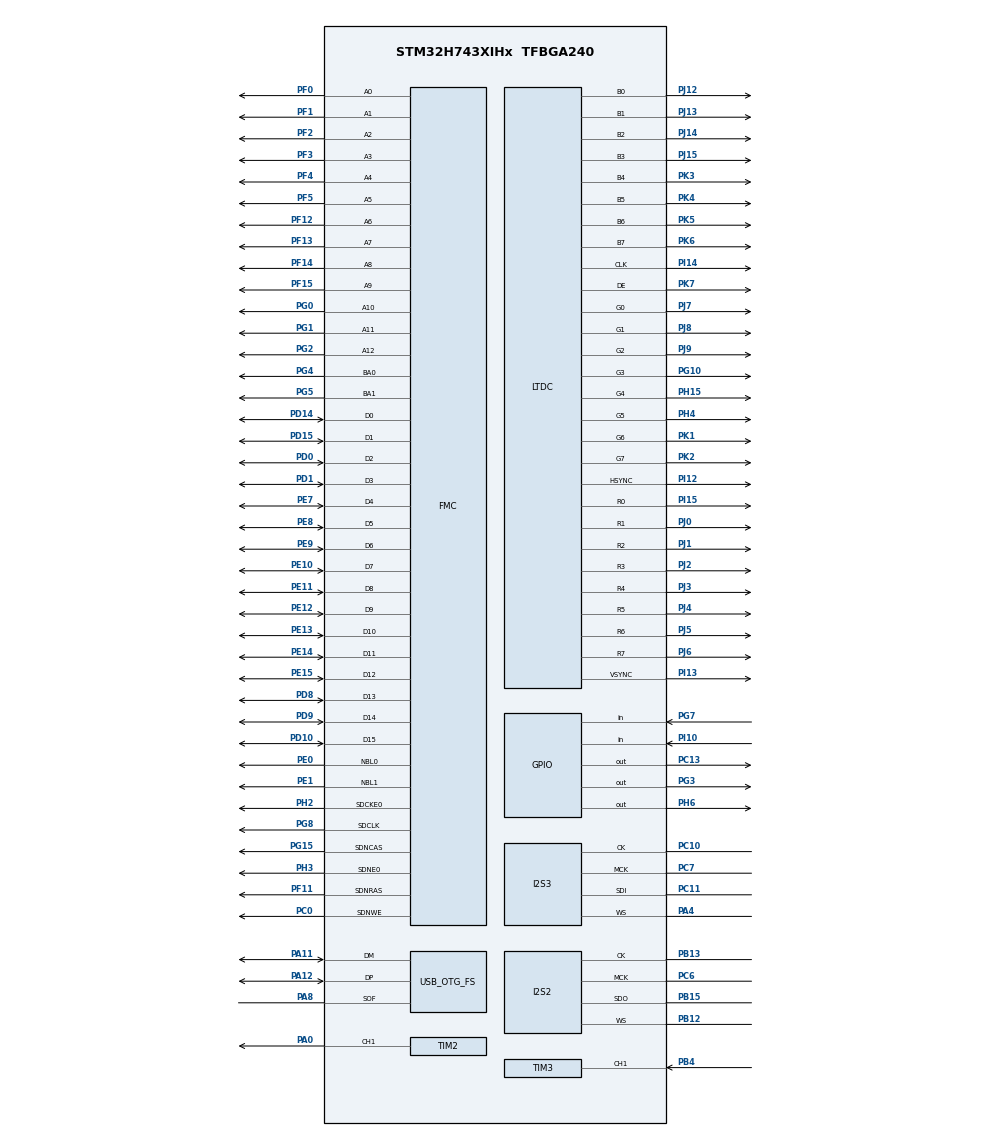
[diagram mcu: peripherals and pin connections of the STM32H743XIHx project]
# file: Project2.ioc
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CORTEX_M7.AccessPermission_S-Cortex_Memory_Protection_Unit_Region1_Settings_S=MPU_REGION_FULL_ACCESS
CORTEX_M7.AccessPermission_Spec=MPU_REGION_FULL_ACCESS
CORTEX_M7.BaseAddress_S-Cortex_Memory_Protection_Unit_Region1_Settings_S=0xC0000000
CORTEX_M7.BaseAddress_Spec=0x24000000
CORTEX_M7.CPU_DCache=Enabled
CORTEX_M7.CPU_ICache=Enabled
CORTEX_M7.DisableExec_Spec=MPU_INSTRUCTION_ACCESS_ENABLE
CORTEX_M7.Enable_S-Cortex_Memory_Protection_Unit_Region1_Settings_S=MPU_REGION_ENABLE
CORTEX_M7.Enable_Spec=MPU_REGION_ENABLE
CORTEX_M7.IsBufferable_S-Cortex_Memory_Protection_Unit_Region1_Settings_S=MPU_ACCESS_BUFFERABLE
CORTEX_M7.IsBufferable_Spec=MPU_ACCESS_BUFFERABLE
CORTEX_M7.IsCacheable_S-Cortex_Memory_Protection_Unit_Region1_Settings_S=MPU_ACCESS_CACHEABLE
CORTEX_M7.IsCacheable_Spec=MPU_ACCESS_CACHEABLE
CORTEX_M7.IsShareable_Spec=MPU_ACCESS_NOT_SHAREABLE
CORTEX_M7.MPU_Control=MPU_HFNMI_PRIVDEF
CORTEX_M7.Number_S-Cortex_Memory_Protection_Unit_Region2_Settings_S=MPU_REGION_NUMBER2
CORTEX_M7.Size_S-Cortex_Memory_Protection_Unit_Region1_Settings_S=MPU_REGION_SIZE_8MB
CORTEX_M7.Size_Spec=MPU_REGION_SIZE_512KB
CORTEX_M7.SubRegionDisable_Spec=0x0
CORTEX_M7.TypeExtField_S-Cortex_Memory_Protection_Unit_Region1_Settings_S=MPU_TEX_LEVEL0
CORTEX_M7.TypeExtField_Spec=MPU_TEX_LEVEL1
CORTEX_M7.default_mode_Activation=1
DMA2D.ColorMode=DMA2D_OUTPUT_RGB565
Dma.Request0=SPI2_TX
Dma.Request1=SPI3_RX
Dma.SPI2_TX.0.Direction=DMA_MEMORY_TO_PERIPH
Dma.SPI2_TX.0.EventEnable=DISABLE
Dma.SPI2_TX.0.FIFOMode=DMA_FIFOMODE_DISABLE
Dma.SPI2_TX.0.Instance=DMA1_Stream0
Dma.SPI2_TX.0.MemDataAlignment=DMA_MDATAALIGN_WORD
Dma.SPI2_TX.0.MemInc=DMA_MINC_ENABLE
Dma.SPI2_TX.0.Mode=DMA_CIRCULAR
Dma.SPI2_TX.0.PeriphDataAlignment=DMA_PDATAALIGN_WORD
Dma.SPI2_TX.0.PeriphInc=DMA_PINC_DISABLE
Dma.SPI2_TX.0.Polarity=HAL_DMAMUX_REQ_GEN_RISING
Dma.SPI2_TX.0.Priority=DMA_PRIORITY_LOW
Dma.SPI2_TX.0.RequestNumber=1
Dma.SPI2_TX.0.SignalID=NONE
Dma.SPI2_TX.0.SyncEnable=DISABLE
Dma.SPI2_TX.0.SyncPolarity=HAL_DMAMUX_SYNC_NO_EVENT
Dma.SPI2_TX.0.SyncRequestNumber=1
Dma.SPI2_TX.0.SyncSignalID=NONE
Dma.SPI3_RX.1.Direction=DMA_PERIPH_TO_MEMORY
Dma.SPI3_RX.1.EventEnable=DISABLE
Dma.SPI3_RX.1.FIFOMode=DMA_FIFOMODE_DISABLE
Dma.SPI3_RX.1.Instance=DMA1_Stream1
Dma.SPI3_RX.1.MemDataAlignment=DMA_MDATAALIGN_WORD
Dma.SPI3_RX.1.MemInc=DMA_MINC_ENABLE
Dma.SPI3_RX.1.Mode=DMA_CIRCULAR
Dma.SPI3_RX.1.PeriphDataAlignment=DMA_PDATAALIGN_WORD
Dma.SPI3_RX.1.PeriphInc=DMA_PINC_DISABLE
Dma.SPI3_RX.1.Polarity=HAL_DMAMUX_REQ_GEN_RISING
Dma.SPI3_RX.1.Priority=DMA_PRIORITY_LOW
Dma.SPI3_RX.1.RequestNumber=1
Dma.SPI3_RX.1.SignalID=NONE
Dma.SPI3_RX.1.SyncEnable=DISABLE
Dma.SPI3_RX.1.SyncPolarity=HAL_DMAMUX_SYNC_NO_EVENT
Dma.SPI3_RX.1.SyncRequestNumber=1
Dma.SPI3_RX.1.SyncSignalID=NONE
FMC.CASLatency1=FMC_SDRAM_CAS_LATENCY_3
FMC.ColumnBitsNumber1=FMC_SDRAM_COLUMN_BITS_NUM_9
FMC.ExitSelfRefreshDelay1=5
FMC.LoadToActiveDelay1=2
FMC.RCDDelay1=2
FMC.RPDelay1=2
FMC.RPDelay2=2
FMC.ReadBurst1=FMC_SDRAM_RBURST_ENABLE
FMC.ReadBurst2=FMC_SDRAM_RBURST_ENABLE
FMC.ReadPipeDelay1=FMC_SDRAM_RPIPE_DELAY_0
FMC.RowCycleDelay1=7
FMC.RowCycleDelay2=7
FMC.SDClockPeriod1=FMC_SDRAM_CLOCK_PERIOD_2
FMC.SDClockPeriod2=FMC_SDRAM_CLOCK_PERIOD_2
FMC.SelfRefreshTime1=4
FMC.WriteRecoveryTime1=3
FREERTOS.Tasks01=DisplayTask,8,2048,DisplayTaskEntry,Default,NULL,Static,DisplayTaskBuffer,DisplayTaskControlBlock;DatacollecTask,40,1024,DatacollecTaskEntry,Default,NULL,Static,DatacollecTaskBuffer,DatacollecTaskControlBlock
FREERTOS.configENABLE_FPU=1
FREERTOS.configUSE_IDLE_HOOK=1
FREERTOS.configUSE_TICK_HOOK=1
I2S2.AudioFreq=I2S_AUDIOFREQ_48K
I2S2.DataFormat=I2S_DATAFORMAT_24B
I2S2.ErrorAudioFreq=0.0 %
I2S2.Instance=SPI$Index
I2S2.RealAudioFreq=48.0 KHz
I2S3.AudioFreq=I2S_AUDIOFREQ_48K
I2S3.DataFormat=I2S_DATAFORMAT_24B
I2S3.ErrorAudioFreq=0.0 %
I2S3.FirstBit=I2S_FIRSTBIT_MSB
I2S3.Instance=SPI$Index
I2S3.RealAudioFreq=48.0 KHz
LTDC.ActiveW=800
LTDC.Alpha_L0=255
LTDC.FBStartAdress_L0=0xC0000000
LTDC.FBStartAdress_L1=0xC00BB800
LTDC.HBP=80
LTDC.HFP=200
LTDC.HSync=1
LTDC.ImageHeight_L0=480
LTDC.ImageHeight_L1=480
LTDC.ImageWidth_L0=800
LTDC.Layers=0
LTDC.PixelFormat_L0=LTDC_PIXEL_FORMAT_RGB565
LTDC.VBP=20
LTDC.VFP=22
LTDC.VSync=1
LTDC.WindowX1_L0=800
LTDC.WindowY1_L0=480
Mcu.Family=STM32H7
Mcu.Name=STM32H743XIHx
Mcu.Package=TFBGA240
NVIC.DMA1_Stream0_IRQn=true\:5\:0\:false\:false\:true\:false\:false\:true\:true
NVIC.DMA1_Stream1_IRQn=true\:5\:0\:false\:false\:true\:false\:false\:true\:true
NVIC.DMA2D_IRQn=true\:5\:0\:false\:false\:true\:true\:true\:true\:true
NVIC.OTG_FS_IRQn=true\:5\:0\:false\:false\:true\:true\:false\:true\:true
NVIC.PriorityGroup=NVIC_PRIORITYGROUP_4
NVIC.SPI2_IRQn=true\:5\:0\:false\:false\:true\:true\:true\:true\:true
NVIC.SPI3_IRQn=true\:5\:0\:false\:false\:true\:true\:true\:true\:true
NVIC.TIM3_IRQn=true\:5\:0\:false\:false\:true\:true\:true\:true\:true
NVIC.TIM6_DAC_IRQn=true\:15\:0\:false\:false\:true\:false\:false\:true\:true
NVIC.TimeBase=TIM6_DAC_IRQn
NVIC.TimeBaseIP=TIM6
PA0.Signal=S_TIM2_CH1_ETR
PA11.Mode=Device_Only
PA11.Signal=USB_OTG_FS_DM
PA12.Mode=Device_Only
PA12.Signal=USB_OTG_FS_DP
PA13\ (JTMS/SWDIO).Mode=Serial_Wire
PA13\ (JTMS/SWDIO).Signal=DEBUG_JTMS-SWDIO
PA14\ (JTCK/SWCLK).Mode=Serial_Wire
PA14\ (JTCK/SWCLK).Signal=DEBUG_JTCK-SWCLK
PA15\ (JTDI).Signal=DEBUG_JTDI
PA4.GPIO_Speed=GPIO_SPEED_FREQ_VERY_HIGH
PA4.Mode=Half_Duplex_Master_Rx
PA4.Signal=I2S3_WS
PA8.Mode=Activate_SOF_FS
PA8.Signal=USB_OTG_FS_SOF
PB12.GPIO_Speed=GPIO_SPEED_FREQ_VERY_HIGH
PB12.Mode=Half_Duplex_Master_Tx
PB12.Signal=I2S2_WS
PB13.GPIO_Speed=GPIO_SPEED_FREQ_VERY_HIGH
PB13.Mode=Half_Duplex_Master_Tx
PB13.Signal=I2S2_CK
PB15.GPIO_Speed=GPIO_SPEED_FREQ_VERY_HIGH
PB15.Mode=Half_Duplex_Master_Tx
PB15.Signal=I2S2_SDO
PB4\ (NJTRST).Signal=S_TIM3_CH1
PC0.Signal=FMC_SDNWE
PC10.GPIO_Speed=GPIO_SPEED_FREQ_VERY_HIGH
PC10.Mode=Half_Duplex_Master_Rx
PC10.Signal=I2S3_CK
PC11.GPIO_Speed=GPIO_SPEED_FREQ_VERY_HIGH
PC11.Mode=Half_Duplex_Master_Rx
PC11.Signal=I2S3_SDI
PC13.Signal=GPIO_Output
PC14-OSC32_IN\ (OSC32_IN).Mode=LSE-External-Oscillator
PC14-OSC32_IN\ (OSC32_IN).Signal=RCC_OSC32_IN
PC15-OSC32_OUT\ (OSC32_OUT).Mode=LSE-External-Oscillator
PC15-OSC32_OUT\ (OSC32_OUT).Signal=RCC_OSC32_OUT
PC6.GPIO_Speed=GPIO_SPEED_FREQ_VERY_HIGH
PC6.Mode=Master_Clock_Activated
PC6.Signal=I2S2_MCK
PC7.GPIO_Speed=GPIO_SPEED_FREQ_VERY_HIGH
PC7.Mode=Master_Clock_Activated
PC7.Signal=I2S3_MCK
PD0.Signal=FMC_D2_DA2
PD1.Signal=FMC_D3_DA3
PD10.Signal=FMC_D15_DA15
PD14.Signal=FMC_D0_DA0
PD15.Signal=FMC_D1_DA1
PD8.Signal=FMC_D13_DA13
PD9.Signal=FMC_D14_DA14
PE0.Signal=FMC_NBL0
PE1.Signal=FMC_NBL1
PE10.Signal=FMC_D7_DA7
PE11.Signal=FMC_D8_DA8
PE12.Signal=FMC_D9_DA9
PE13.Signal=FMC_D10_DA10
PE14.Signal=FMC_D11_DA11
PE15.Signal=FMC_D12_DA12
PE7.Signal=FMC_D4_DA4
PE8.Signal=FMC_D5_DA5
PE9.Signal=FMC_D6_DA6
PF0.Signal=FMC_A0
PF1.Signal=FMC_A1
PF11.Signal=FMC_SDNRAS
PF12.Signal=FMC_A6
PF13.Signal=FMC_A7
PF14.Signal=FMC_A8
PF15.Signal=FMC_A9
PF2.Signal=FMC_A2
PF3.Signal=FMC_A3
PF4.Signal=FMC_A4
PF5.PinAttribute=Free
PF5.Signal=FMC_A5
PG0.Signal=FMC_A10
PG1.Signal=FMC_A11
PG10.GPIO_Speed=GPIO_SPEED_FREQ_VERY_HIGH
PG10.Mode=RGB888
PG10.Signal=LTDC_G3
PG15.Signal=FMC_SDNCAS
PG2.Signal=FMC_A12
PG3.Signal=GPIO_Output
PG4.Signal=FMC_A14_BA0
PG5.Signal=FMC_A15_BA1
PG6.GPIO_Speed=GPIO_SPEED_FREQ_VERY_HIGH
PG6.Signal=QUADSPI_BK1_NCS
PG7.Signal=GPIO_Input
PG8.Signal=FMC_SDCLK
PH0-OSC_IN\ (PH0).Mode=HSE-External-Oscillator
PH0-OSC_IN\ (PH0).PinAttribute=Free
PH0-OSC_IN\ (PH0).Signal=RCC_OSC_IN
PH1-OSC_OUT\ (PH1).Mode=HSE-External-Oscillator
PH1-OSC_OUT\ (PH1).PinAttribute=Free
PH1-OSC_OUT\ (PH1).Signal=RCC_OSC_OUT
PH15.GPIO_Speed=GPIO_SPEED_FREQ_VERY_HIGH
PH15.Mode=RGB888
PH15.Signal=LTDC_G4
PH2.Mode=SdramChipSelect1_1
PH2.Signal=FMC_SDCKE0
PH3.Mode=SdramChipSelect1_1
PH3.Signal=FMC_SDNE0
PH4.GPIO_Speed=GPIO_SPEED_FREQ_VERY_HIGH
PH4.Mode=RGB888
PH4.Signal=LTDC_G5
PH6.Signal=GPIO_Output
PI10.Signal=GPIO_Input
PI12.GPIO_Speed=GPIO_SPEED_FREQ_VERY_HIGH
PI12.Mode=RGB888
PI12.Signal=LTDC_HSYNC
PI13.GPIO_Speed=GPIO_SPEED_FREQ_VERY_HIGH
PI13.Mode=RGB888
PI13.Signal=LTDC_VSYNC
PI14.GPIO_Speed=GPIO_SPEED_FREQ_VERY_HIGH
PI14.Mode=RGB888
PI14.PinAttribute=Free
PI14.Signal=LTDC_CLK
PI15.GPIO_Speed=GPIO_SPEED_FREQ_VERY_HIGH
PI15.Mode=RGB888
PI15.Signal=LTDC_R0
PJ0.GPIO_Speed=GPIO_SPEED_FREQ_VERY_HIGH
PJ0.Mode=RGB888
PJ0.Signal=LTDC_R1
PJ1.GPIO_Speed=GPIO_SPEED_FREQ_VERY_HIGH
PJ1.Mode=RGB888
PJ1.Signal=LTDC_R2
PJ12.Mode=RGB888
PJ12.Signal=LTDC_B0
PJ13.Mode=RGB888
PJ13.Signal=LTDC_B1
PJ14.Mode=RGB888
PJ14.Signal=LTDC_B2
PJ15.Mode=RGB888
PJ15.Signal=LTDC_B3
PJ2.GPIO_Speed=GPIO_SPEED_FREQ_VERY_HIGH
PJ2.Mode=RGB888
PJ2.Signal=LTDC_R3
PJ3.GPIO_Speed=GPIO_SPEED_FREQ_VERY_HIGH
PJ3.Mode=RGB888
PJ3.Signal=LTDC_R4
PJ4.GPIO_Speed=GPIO_SPEED_FREQ_VERY_HIGH
PJ4.Mode=RGB888
PJ4.Signal=LTDC_R5
PJ5.Mode=RGB888
PJ5.Signal=LTDC_R6
PJ6.Mode=RGB888
PJ6.Signal=LTDC_R7
PJ7.Mode=RGB888
PJ7.Signal=LTDC_G0
PJ8.Mode=RGB888
PJ8.Signal=LTDC_G1
PJ9.Mode=RGB888
PJ9.Signal=LTDC_G2
PK1.Mode=RGB888
PK1.Signal=LTDC_G6
PK2.Mode=RGB888
PK2.PinAttribute=Free
PK2.Signal=LTDC_G7
PK3.Mode=RGB888
PK3.Signal=LTDC_B4
PK4.Mode=RGB888
PK4.Signal=LTDC_B5
PK5.Mode=RGB888
PK5.Signal=LTDC_B6
PK6.Mode=RGB888
PK6.Signal=LTDC_B7
PK7.Mode=RGB888
PK7.Signal=LTDC_DE
ProjectManager.HeapSize=0x2000
ProjectManager.StackSize=0x2000
ProjectManager.TargetToolchain=CMake
RCC.ADCCLockSelection=RCC_ADCCLKSOURCE_PLL2
RCC.ADCFreq_Value=80000000
RCC.APB1Freq_Value=120000000
RCC.APB2Freq_Value=120000000
RCC.APB3Freq_Value=120000000
RCC.APB4Freq_Value=120000000
RCC.CECCLockSelection=RCC_CECCLKSOURCE_LSI
RCC.CKPERSourceSelection=RCC_CLKPSOURCE_HSI
RCC.CSI_VALUE=4000000
RCC.CortexFreq_Value=480000000
RCC.D1PPRE=RCC_APB3_DIV2
RCC.D2PPRE1=RCC_APB1_DIV2
RCC.D2PPRE2=RCC_APB2_DIV2
RCC.D3PPRE=RCC_APB4_DIV2
RCC.DFSDMCLockSelection=RCC_DFSDM1CLKSOURCE_D2PCLK1
RCC.DIVM1=4
RCC.DIVM2=4
RCC.DIVM3=25
RCC.DIVN1=60
RCC.DIVN2=10
RCC.DIVN3=96
RCC.DIVP3=5
RCC.DIVR3=7
RCC.DSICLockSelection=RCC_DSICLKSOURCE_PHY
RCC.DSI_PHY_VALUE=12288000
RCC.EXTERNAL_CLOCK_VALUE=12288000
RCC.FDCANCLockSelection=RCC_FDCANCLKSOURCE_PLL
RCC.FMCCLockSelection=RCC_FMCCLKSOURCE_D1HCLK
RCC.HCLKFreq_Value=240000000
RCC.HPRE=RCC_HCLK_DIV2
RCC.HSE_VALUE=25000000
RCC.HSI_VALUE=64000000
RCC.I2C123CLockSelection=RCC_I2C123CLKSOURCE_D2PCLK1
RCC.I2C4CLockSelection=RCC_I2C4CLKSOURCE_D3PCLK1
RCC.LPTIM1CLockSelection=RCC_LPTIM1CLKSOURCE_D2PCLK1
RCC.LPTIM2CLockSelection=RCC_LPTIM2CLKSOURCE_D3PCLK1
RCC.LPTIM345CLockSelection=RCC_LPTIM345CLKSOURCE_D3PCLK1
RCC.LPUART1CLockSelection=RCC_LPUART1CLKSOURCE_D3PCLK1
RCC.PLL2FRACN=0
RCC.PLL3FRACN=0
RCC.PLLFRACN=0
RCC.QSPICLockSelection=RCC_QSPICLKSOURCE_D1HCLK
RCC.RC48_VALUE=48000000
RCC.RCC_MCO1Source=RCC_MCO1SOURCE_HSI
RCC.RCC_MCO2Source=RCC_MCO2SOURCE_SYSCLK
RCC.RNGCLockSelection=RCC_RNGCLKSOURCE_HSI48
RCC.SAI1CLockSelection=RCC_SAI1CLKSOURCE_PLL
RCC.SAI23CLockSelection=RCC_SAI23CLKSOURCE_PLL
RCC.SAI4ACLockSelection=RCC_SAI4ACLKSOURCE_PLL
RCC.SAI4BCLockSelection=RCC_SAI4BCLKSOURCE_PLL
RCC.SPDIFCLockSelection=RCC_SPDIFRXCLKSOURCE_PLL
RCC.SPI123CLockSelection=RCC_SPI123CLKSOURCE_PLL3
RCC.SPI6CLockSelection=RCC_SPI6CLKSOURCE_D3PCLK1
RCC.SWPCLockSelection=RCC_SWPMI1CLKSOURCE_D2PCLK1
RCC.SYSCLKFreq_VALUE=480000000
RCC.SYSCLKSource=RCC_SYSCLKSOURCE_PLLCLK
RCC.Spi45ClockSelection=RCC_SPI45CLKSOURCE_D2PCLK1
RCC.USART16CLockSelection=RCC_USART16CLKSOURCE_D2PCLK2
RCC.USART234578CLockSelection=RCC_USART234578CLKSOURCE_D2PCLK1
RCC.USBCLockSelection=RCC_USBCLKSOURCE_HSI48
RCC.USBFreq_Value=48000000
SH.FMC_A0.0=FMC_A0,13b-sda1
SH.FMC_A1.0=FMC_A1,13b-sda1
SH.FMC_A10.0=FMC_A10,13b-sda1
SH.FMC_A11.0=FMC_A11,13b-sda1
SH.FMC_A12.0=FMC_A12,13b-sda1
SH.FMC_A14_BA0.0=FMC_BA0,FourSdramBanks1
SH.FMC_A15_BA1.0=FMC_BA1,FourSdramBanks1
SH.FMC_A2.0=FMC_A2,13b-sda1
SH.FMC_A3.0=FMC_A3,13b-sda1
SH.FMC_A4.0=FMC_A4,13b-sda1
SH.FMC_A5.0=FMC_A5,13b-sda1
SH.FMC_A6.0=FMC_A6,13b-sda1
SH.FMC_A7.0=FMC_A7,13b-sda1
SH.FMC_A8.0=FMC_A8,13b-sda1
SH.FMC_A9.0=FMC_A9,13b-sda1
SH.FMC_D0_DA0.0=FMC_D0,sd-16b-d1
SH.FMC_D10_DA10.0=FMC_D10,sd-16b-d1
SH.FMC_D11_DA11.0=FMC_D11,sd-16b-d1
SH.FMC_D12_DA12.0=FMC_D12,sd-16b-d1
SH.FMC_D13_DA13.0=FMC_D13,sd-16b-d1
SH.FMC_D14_DA14.0=FMC_D14,sd-16b-d1
SH.FMC_D15_DA15.0=FMC_D15,sd-16b-d1
SH.FMC_D1_DA1.0=FMC_D1,sd-16b-d1
SH.FMC_D2_DA2.0=FMC_D2,sd-16b-d1
SH.FMC_D3_DA3.0=FMC_D3,sd-16b-d1
SH.FMC_D4_DA4.0=FMC_D4,sd-16b-d1
SH.FMC_D5_DA5.0=FMC_D5,sd-16b-d1
SH.FMC_D6_DA6.0=FMC_D6,sd-16b-d1
SH.FMC_D7_DA7.0=FMC_D7,sd-16b-d1
SH.FMC_D8_DA8.0=FMC_D8,sd-16b-d1
SH.FMC_D9_DA9.0=FMC_D9,sd-16b-d1
SH.FMC_NBL0.0=FMC_NBL0,Sd2ByteEnable1
SH.FMC_NBL1.0=FMC_NBL1,Sd2ByteEnable1
SH.FMC_SDCLK.0=FMC_SDCLK,13b-sda1
SH.FMC_SDNCAS.0=FMC_SDNCAS,13b-sda1
SH.FMC_SDNRAS.0=FMC_SDNRAS,13b-sda1
SH.FMC_SDNWE.0=FMC_SDNWE,13b-sda1
SH.S_TIM2_CH1_ETR.0=TIM2_CH1,PWM Generation1 CH1
SH.S_TIM3_CH1.0=TIM3_CH1,Input_Capture1_from_TI1
TIM1.AutoReloadPreload=TIM_AUTORELOAD_PRELOAD_DISABLE
TIM1.Period=65536-1
TIM1.Prescaler=240-1
TIM2.AutoReloadPreload=TIM_AUTORELOAD_PRELOAD_ENABLE
TIM2.Channel-PWM\ Generation1\ CH1=TIM_CHANNEL_1
TIM2.Period=1000-1
TIM2.Prescaler=120-1
TIM3.Channel-Input_Capture1_from_TI1=TIM_CHANNEL_1
USB_DEVICE.CLASS_NAME_FS=AUDIO
USB_DEVICE.USBD_AUDIO_FREQ-AUDIO_FS=48000
USB_DEVICE.VID-AUDIO_FS=11451
USB_DEVICE.VirtualMode-AUDIO_FS=Audio
USB_DEVICE.VirtualModeFS=Audio_FS
USB_OTG_FS.VirtualMode=Device_Only
USB_OTG_FS.dma_enable=DISABLE
VP_CRC_VS_CRC.Mode=CRC_Activate
VP_DMA2D_VS_DMA2D.Mode=DMA2D_Activate
VP_FREERTOS_VS_CMSIS_V2.Mode=CMSIS_V2
VP_MEMORYMAP_VS_MEMORYMAP.Mode=CurAppReg
VP_SYS_VS_tim6.Mode=TIM6
VP_TIM1_VS_ClockSourceINT.Mode=Internal
VP_TIM2_VS_ClockSourceINT.Mode=Internal
VP_TIM3_VS_ClockSourceINT.Mode=Internal
VP_USB_DEVICE_VS_USB_DEVICE_AUDIO_FS.Mode=AUDIO_FS
board=custom

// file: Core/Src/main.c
/* USER CODE BEGIN Header */
/**
  ******************************************************************************
  * @file           : main.c
  * @brief          : Main program body
  ******************************************************************************
  * @attention
  *
  * Copyright (c) 2026 STMicroelectronics.
  * All rights reserved.
  *
  * This software is licensed under terms that can be found in the LICENSE file
  * in the root directory of this software component.
  * If no LICENSE file comes with this software, it is provided AS-IS.
  *
  ******************************************************************************
  */
/* USER CODE END Header */
#include "main.h"
#include "cmsis_os.h"
#include "crc.h"
#include "dma.h"
#include "dma2d.h"
#include "i2s.h"
#include "ltdc.h"
#include "tim.h"
#include "usb_device.h"
#include "gpio.h"
#include "fmc.h"
#include "cpptest.h"
/* USER CODE BEGIN Includes */
#include "lvgl.h"
/* USER CODE END Includes */

void SystemClock_Config(void);
void PeriphCommonClock_Config(void);
static void MPU_Config(void);
void MX_FREERTOS_Init(void);

/* USER CODE BEGIN 0 */
#define FPSCR_FZ_Msk  (1UL << 24)
#define FPSCR_DN_Msk  (1UL << 25)
/* USER CODE END 0 */

int main(void)
{

  /* MPU Configuration--------------------------------------------------------*/
  MPU_Config();

  /* Enable the CPU Cache */

  /* Enable I-Cache---------------------------------------------------------*/
  SCB_EnableICache();

  /* Enable D-Cache---------------------------------------------------------*/
  SCB_EnableDCache();

  /* MCU Configuration--------------------------------------------------------*/

  /* Reset of all peripherals, Initializes the Flash interface and the Systick. */
  HAL_Init();

  /* Configure the system clock */
  SystemClock_Config();

  /* Configure the peripherals common clocks */
  PeriphCommonClock_Config();

  /* Initialize all configured peripherals */
  MX_GPIO_Init();
  MX_DMA_Init();
  MX_FMC_Init();
  MX_LTDC_Init();
  MX_CRC_Init();
  MX_DMA2D_Init();
  MX_TIM1_Init();
  MX_TIM2_Init();
  MX_TIM3_Init();
  MX_I2S2_Init();
  MX_I2S3_Init();
  /* USER CODE BEGIN 2 */

  __set_FPSCR(__get_FPSCR() | FPSCR_FZ_Msk | FPSCR_DN_Msk);
  volatile uint32_t* FPDSCR = (volatile uint32_t*)(0xE000EF3C);
  *FPDSCR |= (1U << 24) | (1U << 25);
  /* USER CODE END 2 */

  /* Init scheduler */
  osKernelInitialize();  /* Call init function for freertos objects (in cmsis_os2.c) */
  MX_FREERTOS_Init();

  /* Start scheduler */
  osKernelStart();

  /* We should never get here as control is now taken by the scheduler */

  /* Infinite loop */
  while (1)
  {

  }
}

void SystemClock_Config(void)
{
  RCC_OscInitTypeDef RCC_OscInitStruct = {0};
  RCC_ClkInitTypeDef RCC_ClkInitStruct = {0};

  /** Supply configuration update enable
  */
  HAL_PWREx_ConfigSupply(PWR_LDO_SUPPLY);

  /** Configure the main internal regulator output voltage
  */
  __HAL_PWR_VOLTAGESCALING_CONFIG(PWR_REGULATOR_VOLTAGE_SCALE0);

  while(!__HAL_PWR_GET_FLAG(PWR_FLAG_VOSRDY)) {}

  /** Initializes the RCC Oscillators according to the specified parameters
  * in the RCC_OscInitTypeDef structure.
  */
  /* HSE 25 MHz on PH0/PH1 (see .ioc). I2S/USB cannot share HSI: USB is
   * SOF-disciplined via HSI48, I2S PLL3 was on raw HSI (~3% error) so
   * LRCK sat near 49750 Hz and the USB ring eventually underran. */
  RCC_OscInitStruct.OscillatorType = RCC_OSCILLATORTYPE_HSI48|RCC_OSCILLATORTYPE_HSE;
  RCC_OscInitStruct.HSEState = RCC_HSE_ON;
  RCC_OscInitStruct.HSI48State = RCC_HSI48_ON;
  RCC_OscInitStruct.PLL.PLLState = RCC_PLL_ON;
  RCC_OscInitStruct.PLL.PLLSource = RCC_PLLSOURCE_HSE;
  RCC_OscInitStruct.PLL.PLLM = 5;
  RCC_OscInitStruct.PLL.PLLN = 192;
  RCC_OscInitStruct.PLL.PLLP = 2;
  RCC_OscInitStruct.PLL.PLLQ = 2;
  RCC_OscInitStruct.PLL.PLLR = 2;
  RCC_OscInitStruct.PLL.PLLRGE = RCC_PLL1VCIRANGE_2;
  RCC_OscInitStruct.PLL.PLLVCOSEL = RCC_PLL1VCOWIDE;
  RCC_OscInitStruct.PLL.PLLFRACN = 0;
  if (HAL_RCC_OscConfig(&RCC_OscInitStruct) != HAL_OK)
  {
    Error_Handler();
  }

  /** Initializes the CPU, AHB and APB buses clocks
  */
  RCC_ClkInitStruct.ClockType = RCC_CLOCKTYPE_HCLK|RCC_CLOCKTYPE_SYSCLK
                              |RCC_CLOCKTYPE_PCLK1|RCC_CLOCKTYPE_PCLK2
                              |RCC_CLOCKTYPE_D3PCLK1|RCC_CLOCKTYPE_D1PCLK1;
  RCC_ClkInitStruct.SYSCLKSource = RCC_SYSCLKSOURCE_PLLCLK;
  RCC_ClkInitStruct.SYSCLKDivider = RCC_SYSCLK_DIV1;
  RCC_ClkInitStruct.AHBCLKDivider = RCC_HCLK_DIV2;
  RCC_ClkInitStruct.APB3CLKDivider = RCC_APB3_DIV2;
  RCC_ClkInitStruct.APB1CLKDivider = RCC_APB1_DIV2;
  RCC_ClkInitStruct.APB2CLKDivider = RCC_APB2_DIV2;
  RCC_ClkInitStruct.APB4CLKDivider = RCC_APB4_DIV2;

  if (HAL_RCC_ClockConfig(&RCC_ClkInitStruct, FLASH_LATENCY_4) != HAL_OK)
  {
    Error_Handler();
  }
}

void PeriphCommonClock_Config(void)
{
  RCC_PeriphCLKInitTypeDef PeriphClkInitStruct = {0};

  /** Initializes the peripherals clock
  */
  PeriphClkInitStruct.PeriphClockSelection = RCC_PERIPHCLK_SPI3|RCC_PERIPHCLK_SPI2
                              |RCC_PERIPHCLK_LTDC;
  /* 25 MHz / 25 * (245 + 6226/8192) = 245.76 MHz VCO
   * P/5 = 49.152 MHz (I2S 48 kHz exact), R/7 = 35.108 MHz (LTDC unchanged). */
  PeriphClkInitStruct.PLL3.PLL3M = 25;
  PeriphClkInitStruct.PLL3.PLL3N = 245;
  PeriphClkInitStruct.PLL3.PLL3P = 5;
  PeriphClkInitStruct.PLL3.PLL3Q = 2;
  PeriphClkInitStruct.PLL3.PLL3R = 7;
  PeriphClkInitStruct.PLL3.PLL3RGE = RCC_PLL3VCIRANGE_0;
  PeriphClkInitStruct.PLL3.PLL3VCOSEL = RCC_PLL3VCOWIDE;
  PeriphClkInitStruct.PLL3.PLL3FRACN = 6226;
  PeriphClkInitStruct.Spi123ClockSelection = RCC_SPI123CLKSOURCE_PLL3;
  if (HAL_RCCEx_PeriphCLKConfig(&PeriphClkInitStruct) != HAL_OK)
  {
    Error_Handler();
  }
}

 /* MPU Configuration */

void MPU_Config(void)
{
  MPU_Region_InitTypeDef MPU_InitStruct = {0};

  /* Disables the MPU */
  HAL_MPU_Disable();

  /** Initializes and configures the Region and the memory to be protected
  */
  MPU_InitStruct.Enable = MPU_REGION_ENABLE;
  MPU_InitStruct.Number = MPU_REGION_NUMBER0;
  MPU_InitStruct.BaseAddress = 0x24000000;
  MPU_InitStruct.Size = MPU_REGION_SIZE_512KB;
  MPU_InitStruct.SubRegionDisable = 0x0;
  MPU_InitStruct.TypeExtField = MPU_TEX_LEVEL1;
  MPU_InitStruct.AccessPermission = MPU_REGION_FULL_ACCESS;
  MPU_InitStruct.DisableExec = MPU_INSTRUCTION_ACCESS_ENABLE;
  MPU_InitStruct.IsShareable = MPU_ACCESS_NOT_SHAREABLE;
  MPU_InitStruct.IsCacheable = MPU_ACCESS_CACHEABLE;
  MPU_InitStruct.IsBufferable = MPU_ACCESS_BUFFERABLE;

  HAL_MPU_ConfigRegion(&MPU_InitStruct);

  /** Initializes and configures the Region and the memory to be protected
  */
  MPU_InitStruct.Number = MPU_REGION_NUMBER1;
  MPU_InitStruct.BaseAddress = 0xC0000000;
  MPU_InitStruct.Size = MPU_REGION_SIZE_8MB;
  MPU_InitStruct.TypeExtField = MPU_TEX_LEVEL1;

  HAL_MPU_ConfigRegion(&MPU_InitStruct);

  MPU_InitStruct.Enable = MPU_REGION_ENABLE;
  MPU_InitStruct.Number = MPU_REGION_NUMBER0;
  MPU_InitStruct.BaseAddress = 0x30000000;
  MPU_InitStruct.Size = MPU_REGION_SIZE_256KB;
  MPU_InitStruct.SubRegionDisable = 0x0;
  MPU_InitStruct.TypeExtField = MPU_TEX_LEVEL1;
  MPU_InitStruct.AccessPermission = MPU_REGION_FULL_ACCESS;
  MPU_InitStruct.DisableExec = MPU_INSTRUCTION_ACCESS_ENABLE;
  MPU_InitStruct.IsShareable = MPU_ACCESS_NOT_SHAREABLE;
  MPU_InitStruct.IsCacheable = MPU_ACCESS_CACHEABLE;
  MPU_InitStruct.IsBufferable = MPU_ACCESS_BUFFERABLE;

  HAL_MPU_ConfigRegion(&MPU_InitStruct);
  /* Enables the MPU */
  HAL_MPU_Enable(MPU_HFNMI_PRIVDEF);

}

void HAL_TIM_PeriodElapsedCallback(TIM_HandleTypeDef *htim)
{
  if (htim->Instance == TIM6)
  {
    HAL_IncTick();
  }
}

void Error_Handler(void)
{
  __disable_irq();
  while (1)
  {
  }
}

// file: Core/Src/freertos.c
/* USER CODE BEGIN Header */
/**
  ******************************************************************************
  * File Name          : freertos.c
  * Description        : Code for freertos applications
  ******************************************************************************
  * @attention
  *
  * Copyright (c) 2026 STMicroelectronics.
  * All rights reserved.
  *
  * This software is licensed under terms that can be found in the LICENSE file
  * in the root directory of this software component.
  * If no LICENSE file comes with this software, it is provided AS-IS.
  *
  ******************************************************************************
  */
/* USER CODE END Header */

#include "FreeRTOS.h"
#include "task.h"
#include "main.h"
#include "cmsis_os.h"

/* USER CODE BEGIN Includes */
#include <math.h>
#include <stdio.h>

#include "lvgl.h"
#include <string.h>
#include <sys/types.h>

#include "i2s.h"
#include "touch_800x480.h"
#include "porting/lv_port_disp.h"
#include "porting/lv_port_indev.h"

#include "../../lvgl_main/ui.h"
#include "tim.h"
#include "benchmark/lv_demo_benchmark.h"
#include "arm_math.h"
#include "effect.h"
#include "usbd_core.h"
#include "main.h"
#include "semphr.h"
#include "usbd_audio_if.h"
#include "usb_device.h"
//#include "gui_guider.h"
//#include "events_init.h"
/* USER CODE END Includes */

typedef StaticTask_t osStaticThreadDef_t;

/* USER CODE BEGIN PD */
#define QSPI_FLASH_TEST_ADDR   0x000000U
#define QSPI_FLASH_TEST_SIZE   256U
#define KEY_COUNT              4U
#define KEY_SCAN_PERIOD_MS     1U
/* temp 存在独立扇区，避免和自检数据撞车 */
#define TEMP_FLASH_ADDR        0x001000U
/* USER CODE END PD */

/* Definitions for DisplayTask */
osThreadId_t DisplayTaskHandle;
uint32_t DisplayTaskBuffer[ 8192 ];
osStaticThreadDef_t DisplayTaskControlBlock;
const osThreadAttr_t DisplayTask_attributes = {
  .name = "DisplayTask",
  .cb_mem = &DisplayTaskControlBlock,
  .cb_size = sizeof(DisplayTaskControlBlock),
  .stack_mem = &DisplayTaskBuffer[0],
  .stack_size = sizeof(DisplayTaskBuffer),
  .priority = (osPriority_t) osPriorityLow,
};
/* Definitions for DatacollecTask */
osThreadId_t DatacollecTaskHandle;
uint32_t DatacollecTaskBuffer[ 1024 ];
osStaticThreadDef_t DatacollecTaskControlBlock;
const osThreadAttr_t DatacollecTask_attributes = {
  .name = "DatacollecTask",
  .cb_mem = &DatacollecTaskControlBlock,
  .cb_size = sizeof(DatacollecTaskControlBlock),
  .stack_mem = &DatacollecTaskBuffer[0],
  .stack_size = sizeof(DatacollecTaskBuffer),
  .priority = (osPriority_t) osPriorityHigh,
};

void DisplayTaskEntry(void *argument);
void DatacollecTaskEntry(void *argument);

extern void MX_USB_DEVICE_Init(void);
void MX_FREERTOS_Init(void); /* (MISRA C 2004 rule 8.1) */

/* Hook prototypes */
void vApplicationIdleHook(void);
void vApplicationTickHook(void);

/* USER CODE BEGIN 2 */
void vApplicationIdleHook( void )
{
   /* vApplicationIdleHook() will only be called if configUSE_IDLE_HOOK is set
   to 1 in FreeRTOSConfig.h. It will be called on each iteration of the idle
   task. It is essential that code added to this hook function never attempts
   to block in any way (for example, call xQueueReceive() with a block time
   specified, or call vTaskDelay()). If the application makes use of the
   vTaskDelete() API function (as this demo application does) then it is also
   important that vApplicationIdleHook() is permitted to return to its calling
   function, because it is the responsibility of the idle task to clean up
   memory allocated by the kernel to any task that has since been deleted. */

  __HAL_RCC_USB_OTG_FS_ULPI_CLK_SLEEP_DISABLE();
  __HAL_RCC_USB_OTG_FS_CLK_SLEEP_ENABLE();
  __WFI();  // 进入休眠
}
/* USER CODE END 2 */

/* USER CODE BEGIN 3 */
#define   LOG_BUFFER_SIZE 256
#define Audio_Buffer_Size 64

volatile static uint32_t tick;
__attribute__((section(".ram"))) float x = 0;
__attribute__((section(".ram"))) float z = 0;
__attribute__((section(".ram"))) int32_t y = 0;
__attribute__((aligned(32)))__attribute__((section(".ram"))) uint8_t USBaudio_buffer[USB_AUDIO_BUFFER_SIZE];
__attribute__((aligned(32)))__attribute__((section(".ram"))) int32_t txaudio_buffer[Audio_Buffer_Size];
__attribute__((aligned(32)))__attribute__((section(".ram"))) int32_t rxaudio_buffer[Audio_Buffer_Size];
__attribute__((aligned(32)))__attribute__((section(".ram"))) uint8_t log_buffer[LOG_BUFFER_SIZE];
__attribute__((aligned(32)))__attribute__((section(".ram"))) float audio_process_buffer[Audio_Buffer_Size/2];
__attribute__((aligned(32)))__attribute__((section(".ram"))) float audio_out_buffer[Audio_Buffer_Size/4];

volatile uint32_t g_audio_cycles = 0;
volatile uint32_t g_audio_blocks = 0;

volatile SemaphoreHandle_t xRxI2SSemaphore;
volatile uint8_t I2S_RX_State;

// lv_ui guider_ui;
void vApplicationTickHook(void)
{
    /* This function will be called by each tick interrupt if
    configUSE_TICK_HOOK is set to 1 in FreeRTOSConfig.h. User code can be
    added here, but the tick hook is called from an interrupt context, so
    code must not attempt to block, and only the interrupt safe FreeRTOS API
    functions can be used (those that end in FromISR()). */

    lv_tick_inc(1);
}

/* USER CODE END 3 */

void MX_FREERTOS_Init(void) {
  /* USER CODE BEGIN Init */
    /* 开启 DWT 周期计数器(CPU 占用测量用,计数值 = CPU 时钟数) */
    CoreDebug->DEMCR |= CoreDebug_DEMCR_TRCENA_Msk;
    DWT->CYCCNT = 0;
    DWT->CTRL   |= DWT_CTRL_CYCCNTENA_Msk;
  /* USER CODE END Init */

  /* Create the thread(s) */
  /* creation of DisplayTask */
  DisplayTaskHandle = osThreadNew(DisplayTaskEntry, NULL, &DisplayTask_attributes);

  /* creation of DatacollecTask */
  DatacollecTaskHandle = osThreadNew(DatacollecTaskEntry, NULL, &DatacollecTask_attributes);

}

void DisplayTaskEntry(void *argument)
{
  //MX_USB_DEVICE_Init();
  /* USER CODE BEGIN DisplayTaskEntry */
    Touch_Init();
    lv_init();
    lv_port_disp_init();
    lv_port_indev_init();
  // setup_ui(&guider_ui);           // 初始化 UI
  // events_init(&guider_ui);
    ui_init();
    //ui_center_labels_create(ui_Screen1);
    //lv_demo_music();

    //ui_buttons_create(ui_Screen1);
    // lv_obj_t * Canvas = ui_Canvas_Creat(ui_Container8);
    /* Infinite loop */
    uint32_t last_cpu_tick = xTaskGetTickCount();
    uint32_t win_t0 = DWT->CYCCNT;
    for (;;)
    {
        Touch_Scan();
        lv_task_handler();
        /* 每秒结算一次音频中断的 CPU 占用率 */
        uint32_t now_tick = xTaskGetTickCount();
        uint32_t ms = (uint32_t)(now_tick - last_cpu_tick);
        if (ms >= 1000)
        {
            uint32_t win_cyc = DWT->CYCCNT - win_t0;
            uint32_t cyc     = g_audio_cycles;
            g_audio_cycles -= cyc;
            uint32_t blocks  = g_audio_blocks;
            g_audio_blocks   = 0;

            uint32_t pct = (win_cyc == 0) ? 0u :
                           (uint32_t)(((uint64_t)cyc * 100u) / win_cyc);
            uint32_t avg = (blocks == 0) ? 0u : cyc / blocks;

            ui_set_cpu_usage(pct, avg);

            win_t0 = DWT->CYCCNT;
            last_cpu_tick = now_tick;
        }

        TickType_t xLastWakeTime = xTaskGetTickCount();
        vTaskDelayUntil(&xLastWakeTime, 13);
    }
  /* USER CODE END DisplayTaskEntry */
}

void DatacollecTaskEntry(void *argument)
{
  /* USER CODE BEGIN DatacollecTaskEntry */
    uint8_t debug;

    TIM3_CaptureResult_t tim3_result;

    osDelay(1000);
    HAL_I2S_Transmit_DMA(&hi2s2,txaudio_buffer,Audio_Buffer_Size);
    HAL_I2S_Receive_DMA(&hi2s3,rxaudio_buffer,Audio_Buffer_Size);
    for (;;)
    {
      //AUDIO_Buffer_Read(USBaudio_buffer,USB_AUDIO_BUFFER_SIZE);

      //HAL_I2S_Transmit(&hi2s2,&y,1,1);
      // TickType_t xLastWakeTime = xTaskGetTickCount();
      // vTaskDelayUntil(&xLastWakeTime, 1);
      ulTaskNotifyTake(pdTRUE, portMAX_DELAY);

      const uint16_t frames = (uint16_t)(Audio_Buffer_Size / 4);

      if (I2S_RX_State == 1)
      {
        uint32_t t0 = DWT->CYCCNT;

        for (uint16_t i = 0; i < frames; i++)
        {
          int32_t s = rxaudio_buffer[2 * i];
          /* 符号扩展 24bit → 32bit，再归一化到 [-1, 1] */
          if (s & 0x800000)
            s |= ~0xFFFFFF;
          else
            s &= 0xFFFFFF;
          audio_process_buffer[i] = (float)s * (1.0f / 8388607.0f);
        }

        effect_process(audio_process_buffer, audio_out_buffer, frames);

        for (uint16_t i = 0; i < frames; i++)
        {
          float x = audio_out_buffer[i];
          if (x > 1.0f) x = 1.0f;
          if (x < -1.0f) x = -1.0f;
          int32_t v = (int32_t)(x * 8388607.0f) & 0xFFFFFF;
          txaudio_buffer[2 * i]     = v;
          txaudio_buffer[2 * i + 1] = v;
        }

        SCB_CleanDCache_by_Addr(txaudio_buffer, sizeof(txaudio_buffer) / 2);

        g_audio_cycles += DWT->CYCCNT - t0;
        g_audio_blocks++;
      }
      else if (I2S_RX_State == 2)
      {
        uint32_t t0 = DWT->CYCCNT;
        const uint16_t base = (uint16_t)(Audio_Buffer_Size / 2);

        for (uint16_t i = 0; i < frames; i++)
        {
          int32_t s = rxaudio_buffer[base + 2 * i];
          if (s & 0x800000)
            s |= ~0xFFFFFF;
          else
            s &= 0xFFFFFF;
          audio_process_buffer[i] = (float)s * (1.0f / 8388607.0f);
        }

        effect_process(audio_process_buffer, audio_out_buffer, frames);

        for (uint16_t i = 0; i < frames; i++)
        {
          float x = audio_out_buffer[i];
          if (x > 1.0f) x = 1.0f;
          if (x < -1.0f) x = -1.0f;
          int32_t v = (int32_t)(x * 8388607.0f) & 0xFFFFFF;
          txaudio_buffer[base + 2 * i]     = v;
          txaudio_buffer[base + 2 * i + 1] = v;
        }

        SCB_CleanDCache_by_Addr((uint32_t *)&txaudio_buffer[base], sizeof(txaudio_buffer) / 2);

        g_audio_cycles += DWT->CYCCNT - t0;
        g_audio_blocks++;
      }
    }
  /* USER CODE END DatacollecTaskEntry */
}

/* USER CODE BEGIN Application */
effect_t* Test_Effect_T;

void HAL_I2S_TxHalfCpltCallback(I2S_HandleTypeDef *hi2s)
{
  // uint32_t t0 = DWT->CYCCNT;   /* 中断处理开始计时 */
  //
  // if (AUDIO_Buffer_Read(USBaudio_buffer,Audio_Buffer_Size) != 0)
  // {
  //   for (uint8_t i = 0; i < Audio_Buffer_Size / 2; i++)
  //   {
  //     txaudio_buffer[i] = 0;
  //   }
  // }
  // else
  // {
  //   for (uint8_t i = 0; i < Audio_Buffer_Size / 4; i++)   /* 16 帧 */
  //   {
  //     int16_t L = (int16_t)(USBaudio_buffer[4 * i] | (USBaudio_buffer[4 * i + 1] << 8));
  //     audio_process_buffer[i] = (float)((int32_t)L << 8) * (1.0f / 8388607.0f);
  //   }
  //
  //   effect_process(audio_process_buffer, audio_out_buffer, Audio_Buffer_Size / 4);
  //
  //   for (uint8_t i = 0; i < Audio_Buffer_Size / 4; i++)
  //   {
  //     int32_t v = (int32_t)(audio_out_buffer[i] * 8388607.0f);
  //     txaudio_buffer[2 * i]     = v;
  //     txaudio_buffer[2 * i + 1] = v;
  //   }
  // }
  // SCB_CleanDCache_by_Addr(txaudio_buffer, sizeof(txaudio_buffer) / 2);
  //
  // g_audio_cycles += DWT->CYCCNT - t0;
  // g_audio_blocks++;

}

void HAL_I2S_TxCpltCallback(I2S_HandleTypeDef *hi2s)
{
  // uint32_t t0 = DWT->CYCCNT;
  //
  // if (AUDIO_Buffer_Read(USBaudio_buffer, Audio_Buffer_Size) != 0)
  // {
  //   for (uint16_t i = Audio_Buffer_Size / 2; i < Audio_Buffer_Size; i++)
  //   {
  //     txaudio_buffer[i] = 0;
  //   }
  // }
  // else
  // {
  //   for (uint16_t i = 0; i < Audio_Buffer_Size / 4; i++)   /* 16 帧 */
  //   {
  //     int16_t L = (int16_t)(USBaudio_buffer[4 * i] | (USBaudio_buffer[4 * i + 1] << 8));
  //     audio_process_buffer[i] = (float)((int32_t)L << 8) * (1.0f / 8388607.0f);
  //   }
  //
  //   effect_process(audio_process_buffer, audio_out_buffer, Audio_Buffer_Size / 4);
  //
  //   for (uint16_t i = 0; i < Audio_Buffer_Size / 4; i++)
  //   {
  //     int32_t v = (int32_t)(audio_out_buffer[i] * 8388607.0f);
  //     txaudio_buffer[Audio_Buffer_Size / 2 + 2 * i]     = v;
  //     txaudio_buffer[Audio_Buffer_Size / 2 + 2 * i + 1] = v;
  //   }
  // }
  // SCB_CleanDCache_by_Addr((uint32_t *)&txaudio_buffer[Audio_Buffer_Size / 2], sizeof(txaudio_buffer) / 2);
  //
  // g_audio_cycles += DWT->CYCCNT - t0;
  // g_audio_blocks++;
}

void HAL_I2S_RxHalfCpltCallback(I2S_HandleTypeDef *hi2s)
{
  I2S_RX_State = 1;
  BaseType_t xHigherPriorityTaskWoken = pdFALSE;

  SCB_InvalidateDCache_by_Addr(rxaudio_buffer,sizeof(rxaudio_buffer) / 2);

  vTaskNotifyGiveFromISR(DatacollecTaskHandle, &xHigherPriorityTaskWoken);
  portYIELD_FROM_ISR(xHigherPriorityTaskWoken);
}
void HAL_I2S_RxCpltCallback(I2S_HandleTypeDef *hi2s)
{
  I2S_RX_State = 2;
  BaseType_t xHigherPriorityTaskWoken = pdFALSE;

  SCB_InvalidateDCache_by_Addr(rxaudio_buffer + Audio_Buffer_Size / 2,sizeof(rxaudio_buffer) / 2);

  vTaskNotifyGiveFromISR(DatacollecTaskHandle, &xHigherPriorityTaskWoken);
  portYIELD_FROM_ISR(xHigherPriorityTaskWoken);
}
// static void QSPI_Flash_SelfTest(void)
// {
//     uint8_t wbuf[QSPI_FLASH_TEST_SIZE];
//     uint8_t rbuf[QSPI_FLASH_TEST_SIZE];
//     uint32_t i;
//     uint32_t mismatch;
//     int8_t ret;
//
//     /* 1. 初始化 QSPI Flash（W25Q64） */
//     ret = QSPI_W25Qxx_Init();
//     if(ret != QSPI_W25Qxx_OK) {
//         ui_center_labels_set_text(0, "QSPI init fail");
//         ui_center_labels_set_text_fmt(1, "err: %d", (int)ret);
//         return;
//     }
//     ui_center_labels_set_text(0, "QSPI init OK");
//
//     /* 2. 擦除测试扇区（4KB） */
//     ret = QSPI_W25Qxx_SectorErase(QSPI_FLASH_TEST_ADDR);
//     if(ret != QSPI_W25Qxx_OK) {
//         ui_center_labels_set_text(1, "Erase fail");
//         ui_center_labels_set_text_fmt(2, "err: %d", (int)ret);
//         return;
//     }
//     ui_center_labels_set_text(1, "Erase OK");
//
//     /* 3. 准备并写入测试数据 */
//     for(i = 0; i < QSPI_FLASH_TEST_SIZE; i++) {
//         wbuf[i] = (uint8_t)(i ^ 0x5AU);
//     }
//     ret = QSPI_W25Qxx_WriteBuffer(wbuf, QSPI_FLASH_TEST_ADDR, QSPI_FLASH_TEST_SIZE);
//     if(ret != QSPI_W25Qxx_OK) {
//         ui_center_labels_set_text(2, "Write fail");
//         ui_center_labels_set_text_fmt(3, "err: %d", (int)ret);
//         return;
//     }
//     ui_center_labels_set_text_fmt(2, "Write %u B OK", (unsigned)QSPI_FLASH_TEST_SIZE);
//
//     /* 4. 读回并校验 */
//     memset(rbuf, 0, sizeof(rbuf));
//     ret = QSPI_W25Qxx_ReadBuffer(rbuf, QSPI_FLASH_TEST_ADDR, QSPI_FLASH_TEST_SIZE);
//     if(ret != QSPI_W25Qxx_OK) {
//         ui_center_labels_set_text(3, "Read fail");
//         return;
//     }
//
//     mismatch = 0;
//     for(i = 0; i < QSPI_FLASH_TEST_SIZE; i++) {
//         if(rbuf[i] != wbuf[i]) {
//             mismatch++;
//         }
//     }
//
//     if(mismatch == 0) {
//         ui_center_labels_set_text(3, "Verify OK");
//     } else {
//         ui_center_labels_set_text_fmt(3, "Verify fail %lu", (unsigned long)mismatch);
//     }
// }

/* USER CODE END Application */
